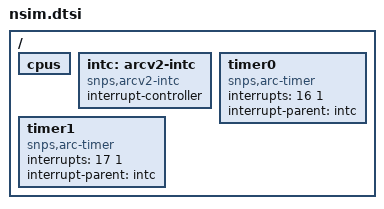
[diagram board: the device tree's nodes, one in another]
/*
 * Copyright (c) 2018, 2019, Synopsys, Inc. All rights reserved.
 *
 * SPDX-License-Identifier: Apache-2.0
 */

/dts-v1/;

#include "skeleton.dtsi"
#include <mem.h>

/ {
	cpus {
		#address-cells = <1>;
		#size-cells = <0>;
	};

	intc: arcv2-intc {
		compatible = "snps,arcv2-intc";
		interrupt-controller;
		#interrupt-cells = <2>;
	};

	timer0: timer0 {
		compatible = "snps,arc-timer";
		interrupts = <16 1>;
		interrupt-parent = <&intc>;
	};

	timer1: timer1 {
		compatible = "snps,arc-timer";
		interrupts = <17 1>;
		interrupt-parent = <&intc>;
	};
};
